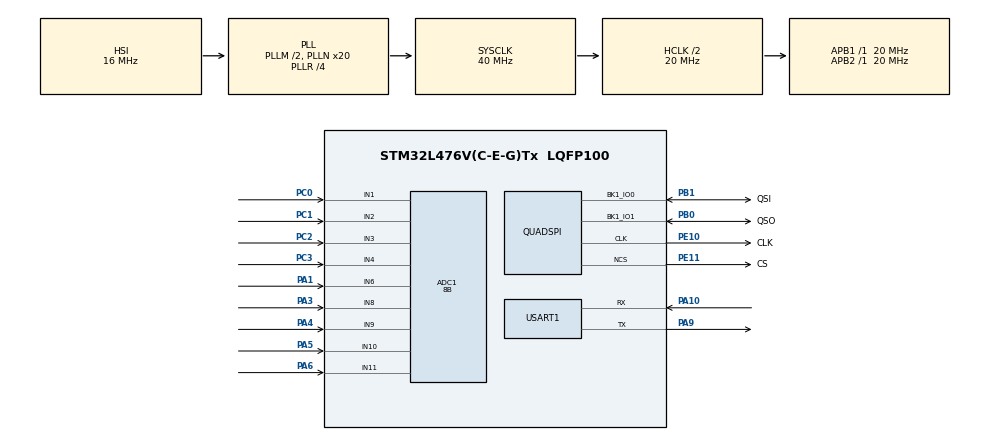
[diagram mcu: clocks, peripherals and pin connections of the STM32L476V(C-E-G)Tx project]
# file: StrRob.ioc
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ADC1.Channel-0\#ChannelRegularConversion=ADC_CHANNEL_1
ADC1.Channel-1\#ChannelRegularConversion=ADC_CHANNEL_1
ADC1.Channel-2\#ChannelRegularConversion=ADC_CHANNEL_1
ADC1.Channel-3\#ChannelRegularConversion=ADC_CHANNEL_1
ADC1.Channel-4\#ChannelRegularConversion=ADC_CHANNEL_1
ADC1.Channel-5\#ChannelRegularConversion=ADC_CHANNEL_1
ADC1.Channel-6\#ChannelRegularConversion=ADC_CHANNEL_1
ADC1.Channel-7\#ChannelRegularConversion=ADC_CHANNEL_1
ADC1.Channel-8\#ChannelRegularConversion=ADC_CHANNEL_1
ADC1.ClockPrescaler=ADC_CLOCK_ASYNC_DIV1
ADC1.DMAContinuousRequests=ENABLE
ADC1.ExternalTrigConv=ADC_EXTERNALTRIG_T1_TRGO2
ADC1.NbrOfConversion=9
ADC1.NbrOfConversionFlag=1
ADC1.OffsetNumber-0\#ChannelRegularConversion=ADC_OFFSET_NONE
ADC1.OffsetNumber-1\#ChannelRegularConversion=ADC_OFFSET_NONE
ADC1.OffsetNumber-2\#ChannelRegularConversion=ADC_OFFSET_NONE
ADC1.OffsetNumber-3\#ChannelRegularConversion=ADC_OFFSET_NONE
ADC1.OffsetNumber-4\#ChannelRegularConversion=ADC_OFFSET_NONE
ADC1.OffsetNumber-5\#ChannelRegularConversion=ADC_OFFSET_NONE
ADC1.OffsetNumber-6\#ChannelRegularConversion=ADC_OFFSET_NONE
ADC1.OffsetNumber-7\#ChannelRegularConversion=ADC_OFFSET_NONE
ADC1.OffsetNumber-8\#ChannelRegularConversion=ADC_OFFSET_NONE
ADC1.Rank-0\#ChannelRegularConversion=1
ADC1.Rank-1\#ChannelRegularConversion=2
ADC1.Rank-2\#ChannelRegularConversion=3
ADC1.Rank-3\#ChannelRegularConversion=4
ADC1.Rank-4\#ChannelRegularConversion=5
ADC1.Rank-5\#ChannelRegularConversion=6
ADC1.Rank-6\#ChannelRegularConversion=7
ADC1.Rank-7\#ChannelRegularConversion=8
ADC1.Rank-8\#ChannelRegularConversion=9
ADC1.Resolution=ADC_RESOLUTION_8B
ADC1.SamplingTime-0\#ChannelRegularConversion=ADC_SAMPLETIME_2CYCLES_5
ADC1.SamplingTime-1\#ChannelRegularConversion=ADC_SAMPLETIME_2CYCLES_5
ADC1.SamplingTime-2\#ChannelRegularConversion=ADC_SAMPLETIME_2CYCLES_5
ADC1.SamplingTime-3\#ChannelRegularConversion=ADC_SAMPLETIME_2CYCLES_5
ADC1.SamplingTime-4\#ChannelRegularConversion=ADC_SAMPLETIME_2CYCLES_5
ADC1.SamplingTime-5\#ChannelRegularConversion=ADC_SAMPLETIME_2CYCLES_5
ADC1.SamplingTime-6\#ChannelRegularConversion=ADC_SAMPLETIME_2CYCLES_5
ADC1.SamplingTime-7\#ChannelRegularConversion=ADC_SAMPLETIME_2CYCLES_5
ADC1.SamplingTime-8\#ChannelRegularConversion=ADC_SAMPLETIME_2CYCLES_5
ADC1.master=1
Dma.ADC1.0.Direction=DMA_PERIPH_TO_MEMORY
Dma.ADC1.0.Instance=DMA1_Channel1
Dma.ADC1.0.MemDataAlignment=DMA_MDATAALIGN_HALFWORD
Dma.ADC1.0.MemInc=DMA_MINC_ENABLE
Dma.ADC1.0.Mode=DMA_CIRCULAR
Dma.ADC1.0.PeriphDataAlignment=DMA_PDATAALIGN_HALFWORD
Dma.ADC1.0.PeriphInc=DMA_PINC_DISABLE
Dma.ADC1.0.Priority=DMA_PRIORITY_LOW
Dma.Request0=ADC1
Mcu.Family=STM32L4
Mcu.Name=STM32L476V(C-E-G)Tx
Mcu.Package=LQFP100
NVIC.ADC1_2_IRQn=true\:0\:0\:false\:false\:true\:true\:true
NVIC.DMA1_Channel1_IRQn=true\:0\:0\:false\:false\:true\:false\:true
NVIC.PriorityGroup=NVIC_PRIORITYGROUP_4
PA1.Signal=ADCx_IN6
PA10.Mode=Asynchronous
PA10.Signal=USART1_RX
PA3.Signal=ADCx_IN8
PA4.Signal=ADCx_IN9
PA5.Signal=ADCx_IN10
PA6.Signal=ADCx_IN11
PA9.Mode=Asynchronous
PA9.Signal=USART1_TX
PB0.GPIO_Label=QSO
PB0.Mode=Single Bank 2IOs
PB0.Signal=QUADSPI_BK1_IO1
PB1.GPIO_Label=QSI
PB1.Mode=Single Bank 2IOs
PB1.Signal=QUADSPI_BK1_IO0
PC0.Signal=ADCx_IN1
PC1.Signal=ADCx_IN2
PC14-OSC32_IN\ (PC14).Mode=LSE-External-Oscillator
PC14-OSC32_IN\ (PC14).Signal=RCC_OSC32_IN
PC15-OSC32_OUT\ (PC15).Mode=LSE-External-Oscillator
PC15-OSC32_OUT\ (PC15).Signal=RCC_OSC32_OUT
PC2.Signal=ADCx_IN3
PC3.Signal=ADCx_IN4
PE10.GPIO_Label=CLK
PE10.Mode=Single Bank 2IOs
PE10.Signal=QUADSPI_CLK
PE11.GPIO_Label=CS
PE11.Mode=Single Bank 2IOs
PE11.Signal=QUADSPI_NCS
PH0-OSC_IN\ (PH0).Mode=HSE-External-Oscillator
PH0-OSC_IN\ (PH0).Signal=RCC_OSC_IN
PH1-OSC_OUT\ (PH1).Mode=HSE-External-Oscillator
PH1-OSC_OUT\ (PH1).Signal=RCC_OSC_OUT
ProjectManager.HeapSize=0x200
ProjectManager.StackSize=0x400
ProjectManager.TargetToolchain=STM32CubeIDE
QUADSPI.ClockMode-Single\ Bank\ 2IOs=QSPI_CLOCK_MODE_0
QUADSPI.ClockPrescaler-Single\ Bank\ 2IOs=1
QUADSPI.FifoThreshold-Single\ Bank\ 2IOs=4
QUADSPI.FlashSize-Single\ Bank\ 2IOs=20
QUADSPI.SampleShifting-Single\ Bank\ 2IOs=QSPI_SAMPLE_SHIFTING_HALFCYCLE
RCC.ADCFreq_Value=60000000
RCC.AHBCLKDivider=RCC_SYSCLK_DIV2
RCC.AHBFreq_Value=20000000
RCC.APB1Freq_Value=20000000
RCC.APB1TimFreq_Value=20000000
RCC.APB2Freq_Value=20000000
RCC.APB2TimFreq_Value=20000000
RCC.CortexFreq_Value=20000000
RCC.HCLKFreq_Value=20000000
RCC.HSE_VALUE=8000000
RCC.HSI_VALUE=16000000
RCC.MSI_VALUE=4000000
RCC.PLLM=2
RCC.PLLN=20
RCC.PLLR=RCC_PLLR_DIV4
RCC.PLLSAI1N=30
RCC.PLLSAI1R=RCC_PLLR_DIV4
RCC.PLLSourceVirtual=RCC_PLLSOURCE_HSI
RCC.PREFETCH_ENABLE=1
RCC.RTCClockSelection=RCC_RTCCLKSOURCE_LSE
RCC.SYSCLKFreq_VALUE=40000000
RCC.SYSCLKSource=RCC_SYSCLKSOURCE_PLLCLK
RCC.USBFreq_Value=120000000
RCC.VCOOutputFreq_Value=160000000
RTC.Format=RTC_FORMAT_BIN
SH.ADCx_IN1.0=ADC1_IN1,IN1-Single-Ended
SH.ADCx_IN10.0=ADC1_IN10,IN10-Single-Ended
SH.ADCx_IN11.0=ADC1_IN11,IN11-Single-Ended
SH.ADCx_IN2.0=ADC1_IN2,IN2-Single-Ended
SH.ADCx_IN3.0=ADC1_IN3,IN3-Single-Ended
SH.ADCx_IN4.0=ADC1_IN4,IN4-Single-Ended
SH.ADCx_IN6.0=ADC1_IN6,IN6-Single-Ended
SH.ADCx_IN8.0=ADC1_IN8,IN8-Single-Ended
SH.ADCx_IN9.0=ADC1_IN9,IN9-Single-Ended
TIM2.Period=19999
TIM2.Prescaler=999
TIM2.TIM_MasterOutputTrigger=TIM_TRGO_UPDATE
USART1.VirtualMode-Asynchronous=VM_ASYNC
VP_RTC_VS_RTC_Activate.Mode=RTC_Enabled
VP_RTC_VS_RTC_Calendar.Mode=RTC_Calendar
VP_TIM2_VS_ClockSourceINT.Mode=Internal
board=STM32L476G-DISCO

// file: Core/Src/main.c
/* USER CODE BEGIN Header */
/**
  ******************************************************************************
  * @file           : main.c
  * @brief          : Main program body
  ******************************************************************************
  * @attention
  *
  * <h2><center>&copy; Copyright (c) 2022 STMicroelectronics.
  * All rights reserved.</center></h2>
  *
  * This software component is licensed by ST under BSD 3-Clause license,
  * the "License"; You may not use this file except in compliance with the
  * License. You may obtain a copy of the License at:
  *                        opensource.org/licenses/BSD-3-Clause
  *
  ******************************************************************************
  */
/* USER CODE END Header */
#include "main.h"
#include "adc.h"
#include "dma.h"
#include "quadspi.h"
#include "rtc.h"
#include "tim.h"
#include "usart.h"
#include "gpio.h"

void SystemClock_Config(void);

int main(void)
{

  /* MCU Configuration--------------------------------------------------------*/

  /* Reset of all peripherals, Initializes the Flash interface and the Systick. */
  HAL_Init();

  /* Configure the system clock */
  SystemClock_Config();

  /* Initialize all configured peripherals */
  MX_GPIO_Init();
  MX_DMA_Init();
  MX_QUADSPI_Init();
  MX_ADC1_Init();
  MX_RTC_Init();
  MX_TIM2_Init();
  MX_USART1_UART_Init();
  /* USER CODE BEGIN 2 */

  // W rtc.c
  //setDate
  //setTime

  /* USER CODE END 2 */

  /* Infinite loop */
  while (1)
  {

  }
}

void SystemClock_Config(void)
{
  RCC_OscInitTypeDef RCC_OscInitStruct = {0};
  RCC_ClkInitTypeDef RCC_ClkInitStruct = {0};
  RCC_PeriphCLKInitTypeDef PeriphClkInit = {0};

  /** Configure LSE Drive Capability
  */
  HAL_PWR_EnableBkUpAccess();
  __HAL_RCC_LSEDRIVE_CONFIG(RCC_LSEDRIVE_LOW);
  /** Initializes the RCC Oscillators according to the specified parameters
  * in the RCC_OscInitTypeDef structure.
  */
  RCC_OscInitStruct.OscillatorType = RCC_OSCILLATORTYPE_HSI|RCC_OSCILLATORTYPE_LSE;
  RCC_OscInitStruct.LSEState = RCC_LSE_ON;
  RCC_OscInitStruct.HSIState = RCC_HSI_ON;
  RCC_OscInitStruct.HSICalibrationValue = RCC_HSICALIBRATION_DEFAULT;
  RCC_OscInitStruct.PLL.PLLState = RCC_PLL_ON;
  RCC_OscInitStruct.PLL.PLLSource = RCC_PLLSOURCE_HSI;
  RCC_OscInitStruct.PLL.PLLM = 2;
  RCC_OscInitStruct.PLL.PLLN = 20;
  RCC_OscInitStruct.PLL.PLLP = RCC_PLLP_DIV7;
  RCC_OscInitStruct.PLL.PLLQ = RCC_PLLQ_DIV2;
  RCC_OscInitStruct.PLL.PLLR = RCC_PLLR_DIV4;
  if (HAL_RCC_OscConfig(&RCC_OscInitStruct) != HAL_OK)
  {
    Error_Handler();
  }
  /** Initializes the CPU, AHB and APB buses clocks
  */
  RCC_ClkInitStruct.ClockType = RCC_CLOCKTYPE_HCLK|RCC_CLOCKTYPE_SYSCLK
                              |RCC_CLOCKTYPE_PCLK1|RCC_CLOCKTYPE_PCLK2;
  RCC_ClkInitStruct.SYSCLKSource = RCC_SYSCLKSOURCE_PLLCLK;
  RCC_ClkInitStruct.AHBCLKDivider = RCC_SYSCLK_DIV2;
  RCC_ClkInitStruct.APB1CLKDivider = RCC_HCLK_DIV1;
  RCC_ClkInitStruct.APB2CLKDivider = RCC_HCLK_DIV1;

  if (HAL_RCC_ClockConfig(&RCC_ClkInitStruct, FLASH_LATENCY_1) != HAL_OK)
  {
    Error_Handler();
  }
  PeriphClkInit.PeriphClockSelection = RCC_PERIPHCLK_RTC|RCC_PERIPHCLK_USART1
                              |RCC_PERIPHCLK_ADC;
  PeriphClkInit.Usart1ClockSelection = RCC_USART1CLKSOURCE_PCLK2;
  PeriphClkInit.AdcClockSelection = RCC_ADCCLKSOURCE_PLLSAI1;
  PeriphClkInit.RTCClockSelection = RCC_RTCCLKSOURCE_LSE;
  PeriphClkInit.PLLSAI1.PLLSAI1Source = RCC_PLLSOURCE_HSI;
  PeriphClkInit.PLLSAI1.PLLSAI1M = 2;
  PeriphClkInit.PLLSAI1.PLLSAI1N = 30;
  PeriphClkInit.PLLSAI1.PLLSAI1P = RCC_PLLP_DIV7;
  PeriphClkInit.PLLSAI1.PLLSAI1Q = RCC_PLLQ_DIV2;
  PeriphClkInit.PLLSAI1.PLLSAI1R = RCC_PLLR_DIV4;
  PeriphClkInit.PLLSAI1.PLLSAI1ClockOut = RCC_PLLSAI1_ADC1CLK;
  if (HAL_RCCEx_PeriphCLKConfig(&PeriphClkInit) != HAL_OK)
  {
    Error_Handler();
  }
  /** Configure the main internal regulator output voltage
  */
  if (HAL_PWREx_ControlVoltageScaling(PWR_REGULATOR_VOLTAGE_SCALE1) != HAL_OK)
  {
    Error_Handler();
  }
}

void Error_Handler(void)
{
}

/************************ (C) COPYRIGHT STMicroelectronics *****END OF FILE****/
